VERSION ""

NS_ :

BS_:

BU_:
VAL_TABLE_ UpDown 1 "Down" 0 "Up" ;

BO_ 2566834817 Roof_Rear_DM1: 8 Vector__XXX

BO_ 2566834818 Roof_Front_DM1: 8 Vector__XXX

BO_ 2566852993 Roof_Rear_CurrentFeedback: 4 Vector__XXX
 SG_ Rear_Right_Motor_Current : 16|16@1- (1,-10000) [-42768|22767] "" Vector__XXX
 SG_ Rear_Left_Motor_Current : 0|16@1- (1,-10000) [-42768|22767] "" Vector__XXX

BO_ 2566852737 Roof_Rear_PositionFeedback: 8 Vector__XXX
 SG_ Rear_Right_Motor_Encoder : 24|20@1+ (1,-524289) [-524289|524286] "" Vector__XXX
 SG_ Rear_Left_Motor_Encoder : 0|20@1+ (1,-524289) [-524289|524286] "" Vector__XXX

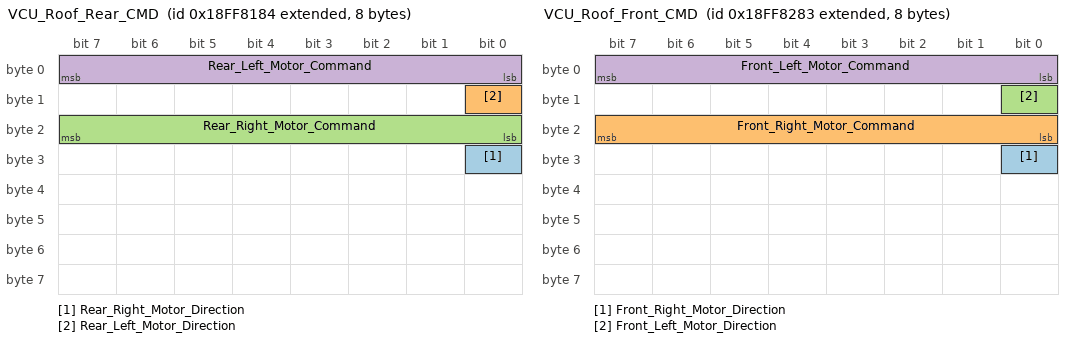
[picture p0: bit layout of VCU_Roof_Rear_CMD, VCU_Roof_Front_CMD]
BO_ 2566881668 VCU_Roof_Rear_CMD: 8 Vector__XXX
 SG_ Rear_Right_Motor_Direction : 24|1@1+ (1,0) [0|1] "" Vector__XXX
 SG_ Rear_Left_Motor_Direction : 8|1@1+ (1,0) [0|1] "" Vector__XXX
 SG_ Rear_Right_Motor_Command : 16|8@1+ (1,0) [0|249] "" Vector__XXX
 SG_ Rear_Left_Motor_Command : 0|8@1+ (1,0) [0|249] "" Vector__XXX

BO_ 2566852994 Roof_Front_CurrentFeedback: 8 Vector__XXX
 SG_ Front_Right_Motor_Current : 16|16@1- (1,-10000) [-42768|22767] "mA" Vector__XXX
 SG_ Front_Left_Motor_Current : 0|16@1- (1,-10000) [-42768|22767] "mA" Vector__XXX

BO_ 2566852738 Roof_Front_PositionFeedback: 8 Vector__XXX
 SG_ Front_Right_Motor_Encoder : 24|20@1+ (1,-524289) [-524289|524286] "" Vector__XXX
 SG_ Front_Left_Motor_Encoder : 0|20@1+ (1,-524289) [-524289|524286] "" Vector__XXX

BO_ 2566881923 VCU_Roof_Front_CMD: 8 Vector__XXX
 SG_ Front_Right_Motor_Direction : 24|1@1+ (1,0) [0|1] "" Vector__XXX
 SG_ Front_Right_Motor_Command : 16|8@1+ (1,0) [0|249] "" Vector__XXX
 SG_ Front_Left_Motor_Direction : 8|1@1+ (1,0) [0|1] "" Vector__XXX
 SG_ Front_Left_Motor_Command : 0|8@1+ (1,0) [0|249] "" Vector__XXX

BA_DEF_  "BusType" STRING ;
BA_DEF_DEF_  "BusType" "CAN";
VAL_ 2566881668 Rear_Right_Motor_Direction 1 "Down" 0 "Up" ;
VAL_ 2566881668 Rear_Left_Motor_Direction 1 "Down" 0 "Up" ;
VAL_ 2566881923 Front_Right_Motor_Direction 1 "Down" 0 "Up" ;
VAL_ 2566881923 Front_Left_Motor_Direction 1 "Down" 0 "Up" ;
